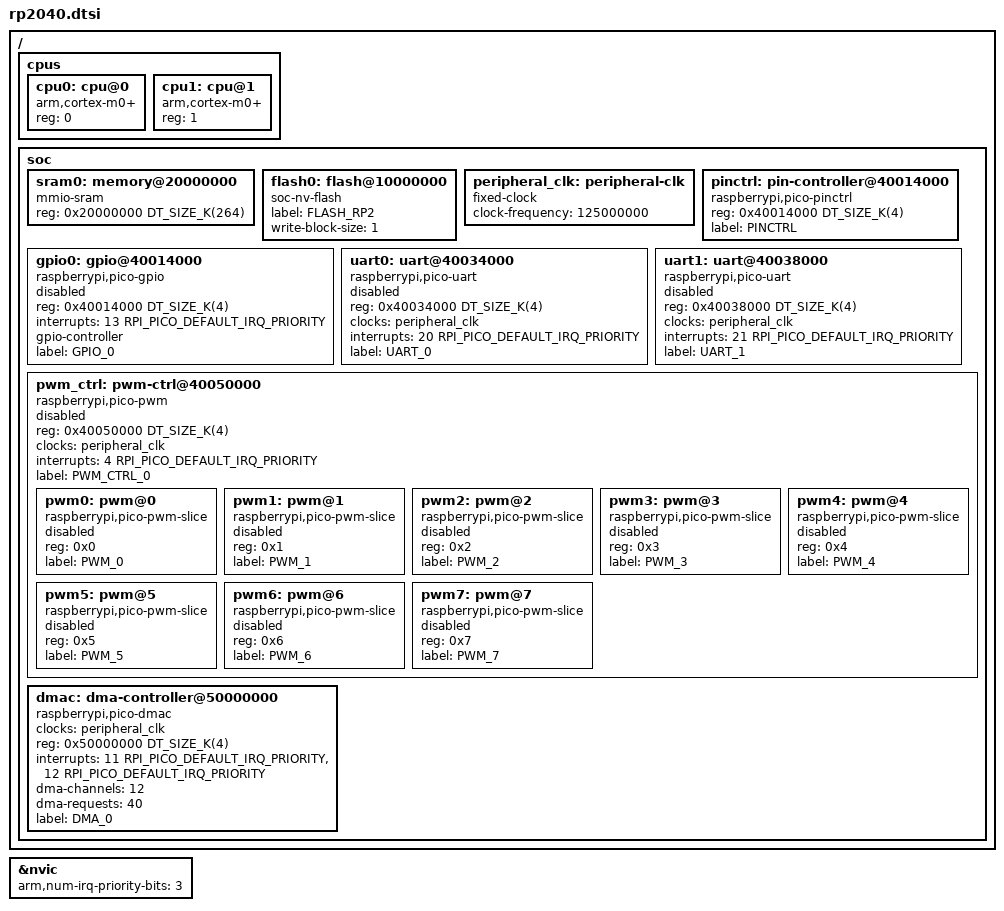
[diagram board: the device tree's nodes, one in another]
/*
 * Copyright (c) 2021 Yonatan Schachter
 *
 * SPDX-License-Identifier: Apache-2.0
 */

#include <arm/armv6-m.dtsi>
#include <dt-bindings/gpio/gpio.h>
#include <mem.h>

#include "rpi_pico_common.dtsi"

/ {
	cpus {
		#address-cells = <1>;
		#size-cells = <0>;

		cpu0: cpu@0 {
			compatible = "arm,cortex-m0+";
			reg = <0>;
		};

		cpu1: cpu@1 {
			compatible = "arm,cortex-m0+";
			reg = <1>;
		};
	};

	soc {
		sram0: memory@20000000 {
			compatible = "mmio-sram";
			reg = <0x20000000 DT_SIZE_K(264)>;
		};

		flash0: flash@10000000 {
			compatible = "soc-nv-flash";
			label = "FLASH_RP2";

			write-block-size = <1>;
		};

		peripheral_clk: peripheral-clk {
			compatible = "fixed-clock";
			clock-frequency = <125000000>;
			#clock-cells = <0>;
		};

		pinctrl: pin-controller@40014000 {
			compatible = "raspberrypi,pico-pinctrl";
			reg = <0x40014000 DT_SIZE_K(4)>;
			status = "okay";
			label = "PINCTRL";
		};

		gpio0: gpio@40014000 {
			compatible = "raspberrypi,pico-gpio";
			reg = <0x40014000 DT_SIZE_K(4)>;
			interrupts = <13 RPI_PICO_DEFAULT_IRQ_PRIORITY>;
			gpio-controller;
			#gpio-cells = <2>;
			label = "GPIO_0";
			status = "disabled";
		};

		uart0: uart@40034000 {
			compatible = "raspberrypi,pico-uart";
			reg = <0x40034000 DT_SIZE_K(4)>;
			clocks = <&peripheral_clk>;
			interrupts = <20 RPI_PICO_DEFAULT_IRQ_PRIORITY>;
			interrupt-names = "uart0";
			label = "UART_0";
			status = "disabled";
		};

		uart1: uart@40038000 {
			compatible = "raspberrypi,pico-uart";
			reg = <0x40038000 DT_SIZE_K(4)>;
			clocks = <&peripheral_clk>;
			interrupts = <21 RPI_PICO_DEFAULT_IRQ_PRIORITY>;
			interrupt-names = "uart1";
			label = "UART_1";
			status = "disabled";
		};

		pwm_ctrl: pwm-ctrl@40050000 {
			compatible = "raspberrypi,pico-pwm";
			reg = <0x40050000 DT_SIZE_K(4)>;
			clocks = <&peripheral_clk>;
			interrupts = <4 RPI_PICO_DEFAULT_IRQ_PRIORITY>;
			interrupt-names = "PWM_IRQ_WRAP";
			label = "PWM_CTRL_0";
			status = "disabled";

			#address-cells = <1>;
			#size-cells = <0>;
			pwm0: pwm@0 {
				compatible = "raspberrypi,pico-pwm-slice";
				reg = <0x0>;
				label = "PWM_0";
				#pwm-cells = <2>;
				status = "disabled";
			};

			pwm1: pwm@1 {
				compatible = "raspberrypi,pico-pwm-slice";
				reg = <0x1>;
				label = "PWM_1";
				#pwm-cells = <2>;
				status = "disabled";
			};

			pwm2: pwm@2 {
				compatible = "raspberrypi,pico-pwm-slice";
				reg = <0x2>;
				label = "PWM_2";
				#pwm-cells = <2>;
				status = "disabled";
			};

			pwm3: pwm@3 {
				compatible = "raspberrypi,pico-pwm-slice";
				reg = <0x3>;
				label = "PWM_3";
				#pwm-cells = <2>;
				status = "disabled";
			};

			pwm4: pwm@4 {
				compatible = "raspberrypi,pico-pwm-slice";
				reg = <0x4>;
				label = "PWM_4";
				#pwm-cells = <2>;
				status = "disabled";
			};

			pwm5: pwm@5 {
				compatible = "raspberrypi,pico-pwm-slice";
				reg = <0x5>;
				label = "PWM_5";
				#pwm-cells = <2>;
				status = "disabled";
			};

			pwm6: pwm@6 {
				compatible = "raspberrypi,pico-pwm-slice";
				reg = <0x6>;
				label = "PWM_6";
				#pwm-cells = <2>;
				status = "disabled";
			};

			pwm7: pwm@7 {
				compatible = "raspberrypi,pico-pwm-slice";
				reg = <0x7>;
				label = "PWM_7";
				#pwm-cells = <2>;
				status = "disabled";
			};
		};

		dmac: dma-controller@50000000 {
			compatible = "raspberrypi,pico-dmac";
			status = "okay";
			clocks = <&peripheral_clk>;
			reg = <0x50000000 DT_SIZE_K(4)>;
			interrupts = <11 RPI_PICO_DEFAULT_IRQ_PRIORITY>,
			             <12 RPI_PICO_DEFAULT_IRQ_PRIORITY>;
			interrupt-names = "DMA_IRQ_0", "DMA_IRQ_1";
			dma-channels = <12>;
			dma-requests = <40>;
			label = "DMA_0";
			#dma-cells = <3>;
		};
	};
};

&nvic {
	arm,num-irq-priority-bits = <3>;
};
